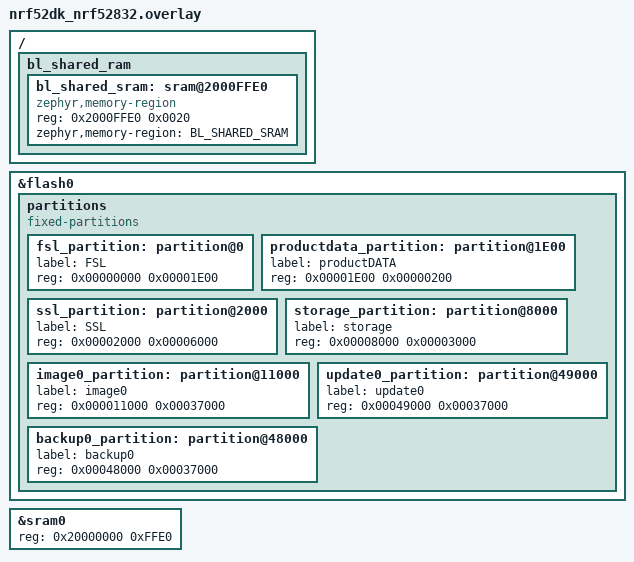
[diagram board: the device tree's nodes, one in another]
/*
 * Copyright (c) 2022 Laczen
 *
 * SPDX-License-Identifier: Apache-2.0
 */

#include "../app.overlay"

/delete-node/ &boot_partition;
/delete-node/ &slot0_partition;
/delete-node/ &slot1_partition;
/delete-node/ &storage_partition;

&flash0 {
	partitions {
		compatible = "fixed-partitions";
		#address-cells = <1>;
		#size-cells = <1>;

		fsl_partition: partition@0 {
			label = "FSL";
			reg = <0x00000000 0x00001E00>;
		};

		productdata_partition: partition@1E00 {
			label = "productDATA";
			reg = <0x00001E00 0x00000200>;
		};

		ssl_partition: partition@2000 {
			label = "SSL";
			reg = <0x00002000 0x00006000>;
		};

		storage_partition: partition@8000 {
			label = "storage";
			reg = <0x00008000 0x00003000>;
		};

		image0_partition: partition@11000 {
			label = "image0";
			reg = <0x000011000 0x00037000>;
		};

		update0_partition: partition@49000 {
			label = "update0";
			reg = <0x00049000 0x00037000>;
		};

		backup0_partition: partition@48000 {
			label = "backup0";
			reg = <0x00048000 0x00037000>;
		};

	};
};

/ {
	bl_shared_ram {
		#address-cells = < 0x1 >;
		#size-cells = < 0x1 >;

		bl_shared_sram: sram@2000FFE0 {
			compatible = "zephyr,memory-region", "mmio-sram";
			reg = < 0x2000FFE0 0x0020 >;
			zephyr,memory-region = "BL_SHARED_SRAM";
		};
	};
};

&sram0 {
	reg = <0x20000000 0xFFE0>;
};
